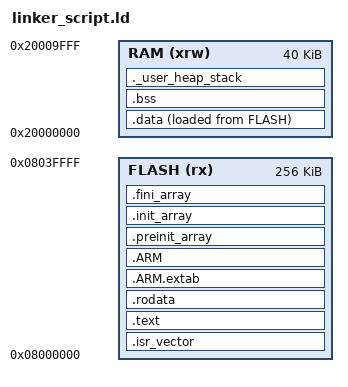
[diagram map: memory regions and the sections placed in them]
/**
 * Minimal linker script for the STM32U0 (Cortex-M0+).
 */

ENTRY(reset_handler)

_stack_end = ORIGIN(RAM) + LENGTH(RAM); /* end of "RAM" Ram type memory */
_min_heap_size = 0x200; /* required amount of heap */
_min_stack_size = 0x400; /* required amount of stack */

MEMORY
{
    RAM         (xrw)   : ORIGIN = 0x20000000,      LENGTH = 40K
    FLASH       (rx)    : ORIGIN = 0x8000000,       LENGTH = 256K
}

SECTIONS
{
    .isr_vector :
    {
        . = ALIGN(4);
        KEEP(*(.isr_vector)) /* Startup code */
        . = ALIGN(4);
    } >FLASH

    .text :
    {
        . = ALIGN(4);
        *(.text)            /* .text sections (code) */
        *(.text*)           /* .text* sections (code) */
        *(.glue_7)          /* glue arm to thumb code */
        *(.glue_7t)         /* glue thumb to arm code */
        *(.eh_frame)

        KEEP (*(.init))
        KEEP (*(.fini))

        . = ALIGN(4);
        _text_end = .;
    } >FLASH

    /* Constant data into "FLASH" Rom type memory */
    .rodata :
    {
        . = ALIGN(4);
        *(.rodata)         /* .rodata sections (constants, strings, etc.) */
        *(.rodata*)        /* .rodata* sections (constants, strings, etc.) */
        . = ALIGN(4);
    } >FLASH

    .ARM.extab (READONLY) :
    {
        . = ALIGN(4);
        *(.ARM.extab* .gnu.linkonce.armextab.*)
        . = ALIGN(4);
    } >FLASH

    .ARM (READONLY) :
    {
        . = ALIGN(4);
        __exidx_start = .;
        *(.ARM.exidx*)
        __exidx_end = .;
        . = ALIGN(4);
    } >FLASH

    .preinit_array (READONLY) :
    {
        . = ALIGN(4);
        PROVIDE_HIDDEN (__preinit_array_start = .);
        KEEP (*(.preinit_array*))
        PROVIDE_HIDDEN (__preinit_array_end = .);
        . = ALIGN(4);
    } >FLASH

    .init_array (READONLY) :
    {
        . = ALIGN(4);
        PROVIDE_HIDDEN (__init_array_start = .);
        KEEP (*(SORT(.init_array.*)))
        KEEP (*(.init_array*))
        PROVIDE_HIDDEN (__init_array_end = .);
        . = ALIGN(4);
    } >FLASH

    .fini_array (READONLY) :
    {
        . = ALIGN(4);
        PROVIDE_HIDDEN (__fini_array_start = .);
        KEEP (*(SORT(.fini_array.*)))
        KEEP (*(.fini_array*))
        PROVIDE_HIDDEN (__fini_array_end = .);
        . = ALIGN(4);
    } >FLASH

    /* Used by the startup to initialize data */
    _init_data_start = LOADADDR(.data);

    /* Initialized data sections into "RAM" Ram type memory */
    .data :
    {
        . = ALIGN(4);
        _data_start = .;
        *(.data)
        *(.data*)
        *(.RamFunc)
        *(.RamFunc*)

        . = ALIGN(4);
        _data_end = .;

    } >RAM AT> FLASH

    /* Uninitialized data section into "RAM" Ram type memory */
    . = ALIGN(4);
    .bss :
    {
        _bss_start = .;
        __bss_start__ = _bss_start;
        *(.bss)
        *(.bss*)
        *(COMMON)

        . = ALIGN(4);
        _bss_end = .;
        __bss_end__ = _bss_end;
    } >RAM

    /* User_heap_stack section, used to check that there is enough "RAM" Ram  type memory left */
    ._user_heap_stack :
    {
        . = ALIGN(8);
        PROVIDE ( end = . );
        PROVIDE ( _end = . );
        . = . + _min_heap_size;
        . = . + _min_stack_size;
        . = ALIGN(8);
    } >RAM

    /* Remove information from the compiler libraries */
    /DISCARD/ :
    {
        libc.a ( * )
        libm.a ( * )
        libgcc.a ( * )
    }

    .ARM.attributes 0 : { *(.ARM.attributes) }
}
